# SPI4 register map
Registers from a debugger description file.
Registers are 32-bit, access not given, no defined reset value unless marked. A register's access mark holds for its fields unless they carry their own. Addresses are absolute; registers are grouped by the start of their names; lines under a group give offsets from that group; [hi:lo] are bit positions; {n}, {i} and the like mark numbered series; 'fields as' and 'values as' point back to an identical list; <NAME> marks a mode.

## SPI4
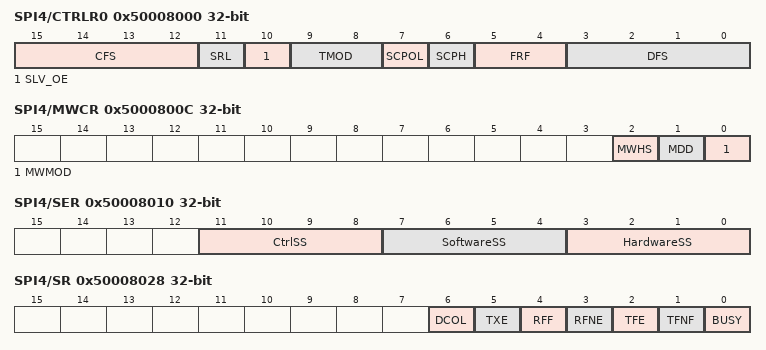
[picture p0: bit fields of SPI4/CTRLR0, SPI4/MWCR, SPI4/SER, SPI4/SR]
0x50008000 SPI4/CTRLR0
  [15:12] CFS, [11] SRL, [10] SLV_OE, [9:8] TMOD, [7] SCPOL, [6] SCPH, [5:4] FRF, [3:0] DFS
0x50008004 SPI4/CTRLR1
  [15:0] NDF
0x50008008 SPI4/SSIENR
  [0] SSIENR
0x5000800C SPI4/MWCR
  [2] MWHS, [1] MDD, [0] MWMOD
0x50008010 SPI4/SER
  [11:8] CtrlSS, [7:4] SoftwareSS, [3:0] HardwareSS
0x50008014 SPI4/BAUDR
  [15:0] SCKDV
0x50008018 SPI4/TXFTLR
  [3:0] TFT
0x5000801C SPI4/RXFTLR
  [3:0] RFT
0x50008020 SPI4/TXFLR ro
  [3:0] TXTFL
0x50008024 SPI4/RXFLR ro
  [3:0] RXTFL
0x50008028 SPI4/SR ro
  [6] DCOL, [5] TXE, [4] RFF, [3] RFNE, [2] TFE, [1] TFNF, [0] BUSY
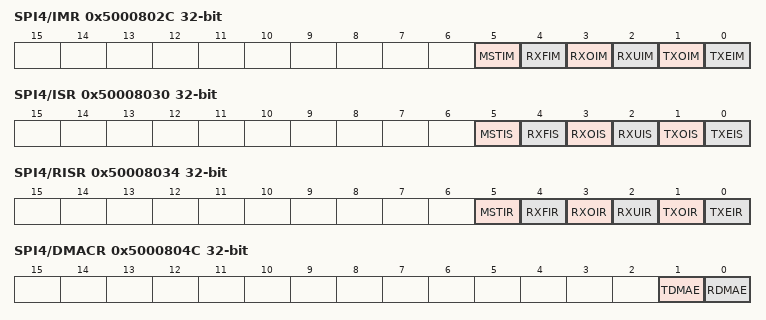
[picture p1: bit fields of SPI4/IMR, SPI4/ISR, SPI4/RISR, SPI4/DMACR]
0x5000802C SPI4/IMR
  [5] MSTIM, [4] RXFIM, [3] RXOIM, [2] RXUIM, [1] TXOIM, [0] TXEIM
0x50008030 SPI4/ISR ro
  [5] MSTIS, [4] RXFIS, [3] RXOIS, [2] RXUIS, [1] TXOIS, [0] TXEIS
0x50008034 SPI4/RISR ro
  [5] MSTIR, [4] RXFIR, [3] RXOIR, [2] RXUIR, [1] TXOIR, [0] TXEIR
0x50008038 SPI4/TXOICR ro
  [0] TXOICR
0x5000803C SPI4/RXOICR ro
  [0] RXOICR
0x50008040 SPI4/RXUICR ro
  [0] RXUICR
0x50008044 SPI4/MSTICR ro
  [0] MSTICR
0x50008048 SPI4/ICR ro
  [0] ICR
0x5000804C SPI4/DMACR
  [1] TDMAE, [0] RDMAE
0x50008050 SPI4/DMATDLR
  [3:0] DMATDLR
0x50008054 SPI4/DMARDLR
  [3:0] DMARDLR
0x50008058 SPI4/IDR ro
  [31:0] ICR
0x5000805C SPI4/SSI_COMP_VERSION ro
0x50008060 SPI4/DR
  [15:0] DR
0x500080F0 SPI4/RX_SAMPLE_DLY
  [7:0] RX_Sample_Delay
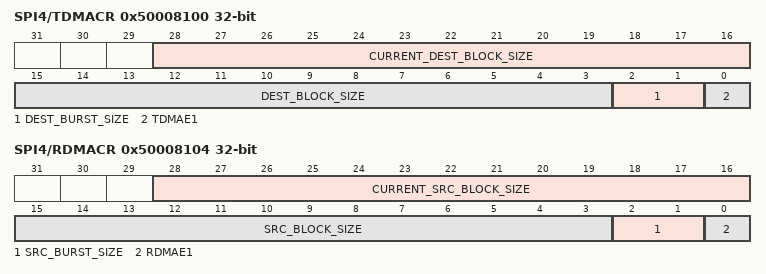
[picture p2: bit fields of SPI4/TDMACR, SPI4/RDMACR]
0x50008100 SPI4/TDMACR
  [28:16] CURRENT_DEST_BLOCK_SIZE, [15:3] DEST_BLOCK_SIZE, [2:1] DEST_BURST_SIZE, [0] TDMAE1
0x50008104 SPI4/RDMACR
  [28:16] CURRENT_SRC_BLOCK_SIZE, [15:3] SRC_BLOCK_SIZE, [2:1] SRC_BURST_SIZE, [0] RDMAE1
